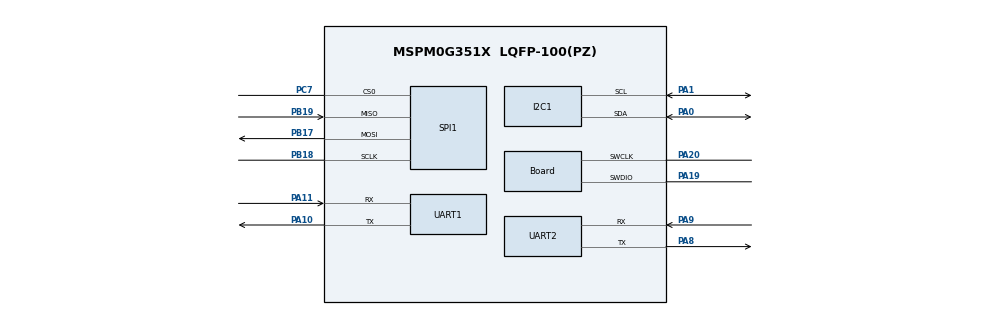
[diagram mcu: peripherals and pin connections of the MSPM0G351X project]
/**
 * @cliArgs --device "MSPM0G351X" --part "Default" --package "LQFP-100(PZ)" --product "mspm0_sdk@2.11.00.07"
 * @versions {"tool":"1.26.2+4477"}
 */

/**
 * Import the modules used in this configuration.
 */
const I2C    = scripting.addModule("/ti/driverlib/I2C", {}, false);
const I2C1   = I2C.addInstance();
const SPI    = scripting.addModule("/ti/driverlib/SPI", {}, false);
const SPI1   = SPI.addInstance();
const SYSCTL = scripting.addModule("/ti/driverlib/SYSCTL");
const UART   = scripting.addModule("/ti/driverlib/UART", {}, false);
const UART1  = UART.addInstance();
const UART2  = UART.addInstance();

/**
 * Write custom configuration values to the imported modules.
 */
I2C1.$name                     = "I2C_0";
I2C1.basicEnableController     = true;
I2C1.peripheral.sdaPin.$assign = "PA0";
I2C1.peripheral.sclPin.$assign = "PA1";
I2C1.sdaPinConfig.$name        = "ti_driverlib_gpio_GPIOPinGeneric8";
I2C1.sclPinConfig.$name        = "ti_driverlib_gpio_GPIOPinGeneric9";

const Board                       = scripting.addModule("/ti/driverlib/Board", {}, false);
Board.peripheral.$assign          = "DEBUGSS";
Board.peripheral.swclkPin.$assign = "PA20";
Board.peripheral.swdioPin.$assign = "PA19";

SPI1.$name                      = "SPI_0";
SPI1.targetBitRate              = 1000000;
SPI1.peripheral.sclkPin.$assign = "PB18";
SPI1.peripheral.mosiPin.$assign = "PB17";
SPI1.peripheral.misoPin.$assign = "PB19";
SPI1.peripheral.cs0Pin.$assign  = "PC7";
SPI1.sclkPinConfig.$name        = "ti_driverlib_gpio_GPIOPinGeneric4";
SPI1.mosiPinConfig.$name        = "ti_driverlib_gpio_GPIOPinGeneric5";
SPI1.misoPinConfig.$name        = "ti_driverlib_gpio_GPIOPinGeneric6";
SPI1.cs0PinConfig.$name         = "ti_driverlib_gpio_GPIOPinGeneric7";

SYSCTL.forceDefaultClkConfig = true;
UART1.$name                    = "UART_0";
UART1.rxFifoThreshold          = "DL_UART_RX_FIFO_LEVEL_ONE_ENTRY";
UART1.enableDMARX              = false;
UART1.enableDMATX              = false;
UART1.enabledInterrupts        = ["RX"];
UART1.peripheral.$assign       = "UART0";
UART1.peripheral.rxPin.$assign = "PA11";
UART1.peripheral.txPin.$assign = "PA10";
UART1.txPinConfig.$name        = "ti_driverlib_gpio_GPIOPinGeneric0";
UART1.rxPinConfig.$name        = "ti_driverlib_gpio_GPIOPinGeneric1";

UART2.$name                    = "UART_1";
UART2.targetBaudRate           = 115200;
UART2.enabledInterrupts        = ["RX"];
UART2.peripheral.rxPin.$assign = "PA9";
UART2.peripheral.txPin.$assign = "PA8";
UART2.txPinConfig.$name        = "ti_driverlib_gpio_GPIOPinGeneric2";
UART2.rxPinConfig.$name        = "ti_driverlib_gpio_GPIOPinGeneric3";

const ProjectConfig              = scripting.addModule("/ti/project_config/ProjectConfig", {}, false);
ProjectConfig.migrationCondition = true;

/**
 * Pinmux solution for unlocked pins/peripherals. This ensures that minor changes to the automatic solver in a future
 * version of the tool will not impact the pinmux you originally saw.  These lines can be completely deleted in order to
 * re-solve from scratch.
 */
I2C1.peripheral.$suggestSolution              = "I2C0";
SPI1.peripheral.$suggestSolution              = "SPI0";
SYSCTL.peripheral.$suggestSolution            = "SYSCTL";
UART2.peripheral.$suggestSolution             = "UART1";
